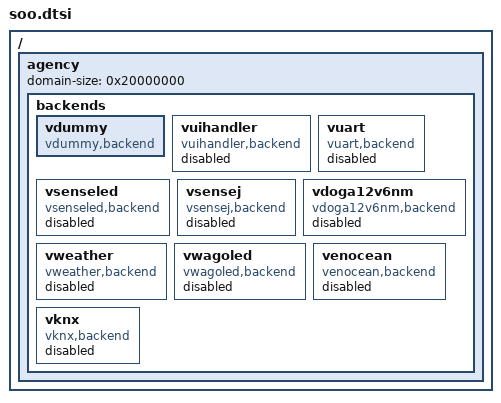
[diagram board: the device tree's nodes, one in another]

/ {

	agency: agency {
	
		domain-size = <0x20000000>; /* 512 MB */	
				
		/* Backends */

		backends {

			vdummy {
				compatible = "vdummy,backend";
				status = "ok";
			};
	
			vuihandler {
				compatible = "vuihandler,backend";
				status = "disabled";
			};
    
			vuart {
				compatible = "vuart,backend";
				status = "disabled";
			};
			
			vsenseled {
            	compatible = "vsenseled,backend";
            	status = "disabled";
        	};
			
        	vsensej {
            	compatible = "vsensej,backend";
            	status = "disabled";
        	};
			
			vdoga12v6nm {
            	compatible = "vdoga12v6nm,backend";
            	status = "disabled";
            };
            
            vweather {
            	compatible = "vweather,backend";
            	status = "disabled";
        	};

			vwagoled {
				compatible = "vwagoled,backend";
				status = "disabled";
			};

			venocean {
				compatible = "venocean,backend";
				status = "disabled";
			};

			vknx {
				compatible = "vknx,backend";
				status = "disabled";
			};

		};
	};
	
};
